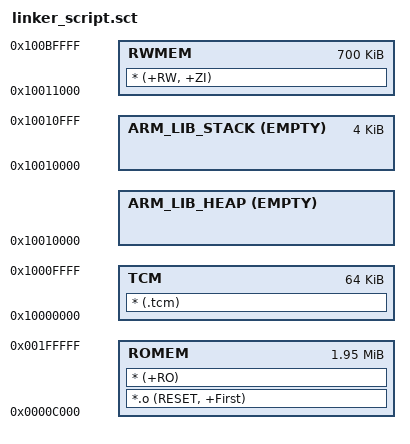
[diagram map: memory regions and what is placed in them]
;******************************************************************************
;
; Scatter file for Keil linker configuration.
;
;******************************************************************************
LR_1 0x0000C000
{
    ROMEM 0x0000C000 0x001F4000
    {
        *.o (RESET, +First)
        * (+RO)
    }

    RWMEM 0x10011000 0x000AF000
    {
        * (+RW, +ZI)
    }

    TCM 0x10000000 0x00010000
    {
        * (.tcm)
    }

    ; Zero-length heap (the legacy startup reserved no heap).  Placed at the
    ; stack-region base so the C library has a defined, non-overlapping heap.
    ARM_LIB_HEAP 0x10010000 EMPTY 0x00000000
    {
    }

    ; 4 KB stack growing down from 0x10011000 to 0x10010000.  __INITIAL_SP
    ; (Image$$ARM_LIB_STACK$$ZI$$Limit) resolves to 0x10011000.
    ARM_LIB_STACK 0x10011000 EMPTY -0x00001000
    {
    }
}
